VERSION ""

NS_ :

BS_:

BU_: ECU Motor PowerAux Solar MotorController

BO_ 256 AuxBatteryStatus: 3 PowerAux
 SG_ aux_voltage : 0|16@1+ (1,0) [0|256] "mV" Vector__XXX
 SG_ percent_full : 16|8@1+ (1,0) [0|0] "hex%" Vector__XXX

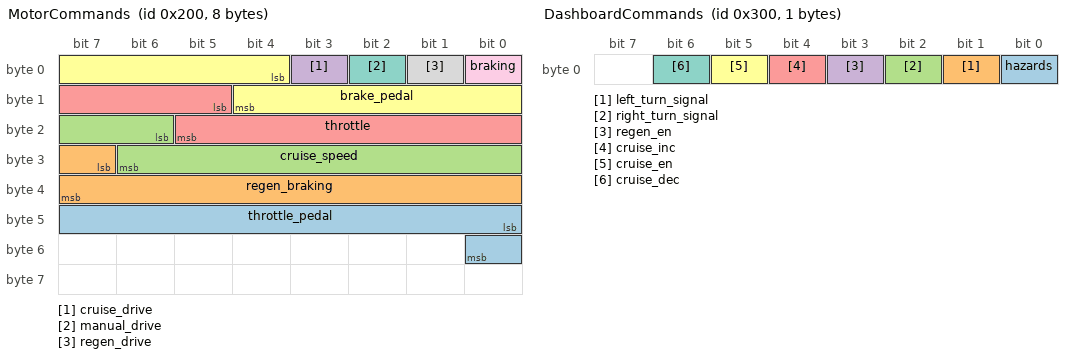
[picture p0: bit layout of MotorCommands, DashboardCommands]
BO_ 512 MotorCommands: 8 ECU
 SG_ throttle_pedal : 40|9@1+ (1,0) [0|256] "" Vector__XXX
 SG_ regen_braking : 31|9@1+ (1,0) [0|256] "" Vector__XXX
 SG_ cruise_speed : 22|9@1+ (1,0) [0|256] "" Vector__XXX
 SG_ cruise_drive : 3|1@1+ (1,0) [0|0] "" Vector__XXX
 SG_ throttle : 13|9@1+ (1,0) [0|256] "" Vector__XXX
 SG_ brake_pedal : 4|9@1+ (1,0) [0|256] "" Vector__XXX
 SG_ manual_drive : 2|1@1+ (1,0) [0|0] "" Vector__XXX
 SG_ regen_drive : 1|1@1+ (1,0) [0|0] "" Vector__XXX
 SG_ braking : 0|1@1+ (1,0) [0|0] "" Vector__XXX

BO_ 768 DashboardCommands: 1 ECU
 SG_ hazards : 0|1@1+ (1,0) [0|0] "" Vector__XXX
 SG_ left_turn_signal : 1|1@1+ (1,0) [0|0] "" Vector__XXX
 SG_ right_turn_signal : 2|1@1+ (1,0) [0|0] "" Vector__XXX
 SG_ regen_en : 3|1@1+ (1,0) [0|0] "" Vector__XXX
 SG_ cruise_inc : 4|1@1+ (1,0) [0|0] "" Vector__XXX
 SG_ cruise_en : 5|1@1+ (1,0) [0|0] "" Vector__XXX
 SG_ cruise_dec : 6|1@1+ (1,0) [0|0] "" Vector__XXX

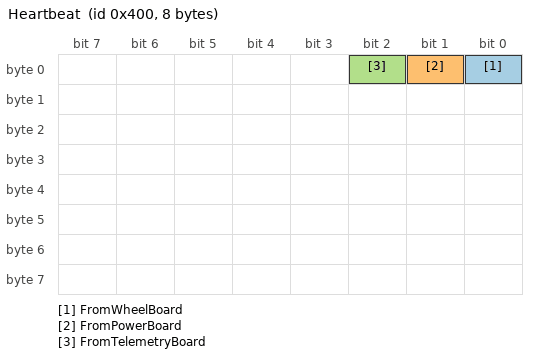
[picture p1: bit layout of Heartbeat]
BO_ 1024 Heartbeat: 8 Vector__XXX
 SG_ FromWheelBoard : 0|1@1+ (1,0) [0|0] "" Vector__XXX
 SG_ FromPowerBoard : 1|1@1+ (1,0) [0|0] "" Vector__XXX
 SG_ FromTelemetryBoard : 2|1@1+ (1,0) [0|0] "" Vector__XXX

BO_ 1280 ChargingMode: 1 Vector__XXX
 SG_ ChargingModeEnable : 0|1@1+ (1,0) [0|0] "" Vector__XXX

BA_DEF_  "BusType" STRING ;
BA_DEF_DEF_  "BusType" "CAN";
